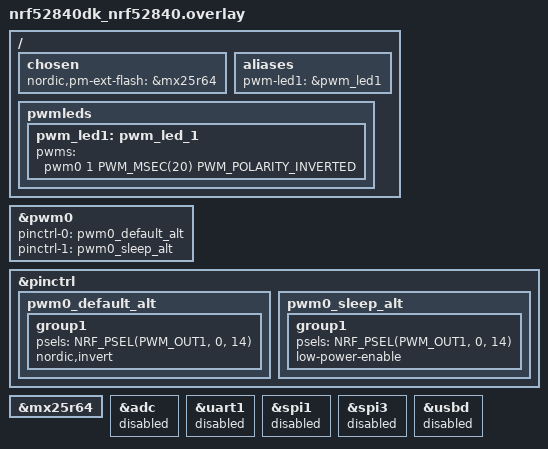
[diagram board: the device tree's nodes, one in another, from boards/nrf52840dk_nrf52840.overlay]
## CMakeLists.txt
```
#
# Copyright (c) 2021 Nordic Semiconductor ASA
#
# SPDX-License-Identifier: LicenseRef-Nordic-5-Clause
#

cmake_minimum_required(VERSION 3.20.0)

include(${CMAKE_CURRENT_LIST_DIR}/../../cmake/find_zephyr.cmake)

project(matter-light-bulb)

# NORDIC SDK APP START

# Include all source files that are located in the Matter common directory.
include(${ZEPHYR_NCS_MATTER_MODULE_DIR}/cmake/sample.cmake)

ncs_get_zap_parent_dir(ZAP_PARENT_DIR)

target_include_directories(app PRIVATE
  src
  ${ZAP_PARENT_DIR}
)

target_sources(app PRIVATE
  src/app_task.cpp
  src/main.cpp
  src/zcl_callbacks.cpp
  ${CHIP_ROOT}/src/app/persistence/DeferredAttributePersistenceProvider.cpp
)

ncs_configure_data_model()
# NORDIC SDK APP END
```

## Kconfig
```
#
# Copyright (c) 2022 Nordic Semiconductor
#
# SPDX-License-Identifier: LicenseRef-Nordic-5-Clause
#
mainmenu "Matter nRF Connect Light Bulb Example Application"

# Sample configuration used for Thread networking
if OPENTHREAD

choice OPENTHREAD_NORDIC_LIBRARY_CONFIGURATION
	default OPENTHREAD_NORDIC_LIBRARY_FTD
endchoice

choice OPENTHREAD_DEVICE_TYPE
	default OPENTHREAD_FTD
endchoice

choice OPENTHREAD_IMPLEMENTATION
	default OPENTHREAD_SOURCES
endchoice

endif # OPENTHREAD

config CHIP_WIFI
	default y if SHIELD_NRF7002EB2

source "$(ZEPHYR_CONNECTEDHOMEIP_MODULE_DIR)/config/nrfconnect/chip-module/Kconfig.features"
source "$(ZEPHYR_CONNECTEDHOMEIP_MODULE_DIR)/config/nrfconnect/chip-module/Kconfig.defaults"
source "Kconfig.zephyr"
```

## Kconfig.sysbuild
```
#
# Copyright (c) 2023 Nordic Semiconductor ASA
#
# SPDX-License-Identifier: LicenseRef-Nordic-5-Clause
#

#### Radio core selection
config NRF_DEFAULT_IPC_RADIO
	default y

# Enable IEEE802.15.4 serialization to network core
# This config automatically pulls in the `overlay-802154.conf` in the ipc_radio image
config NETCORE_IPC_RADIO_IEEE802154
	default y if SOC_SERIES_NRF53 && !WIFI_NRF70

# Enable Bluetooth serialization to network core
# This config automatically pulls in the `overlay-bt_hci_ipc.conf` in the ipc_radio image
config NETCORE_IPC_RADIO_BT_HCI_IPC
	default y if SOC_SERIES_NRF53

#### Bootloader
choice BOOTLOADER
	default BOOTLOADER_MCUBOOT if !BOARD_NRF21540DK && !BOARD_NATIVE_SIM
endchoice

if BOOTLOADER_MCUBOOT

#### DFU multi-image support
config DFU_MULTI_IMAGE_PACKAGE_BUILD
	default y

config DFU_MULTI_IMAGE_PACKAGE_APP
	default y

#### DFU network core configuration
if SOC_SERIES_NRF53

choice MCUBOOT_MODE
	default MCUBOOT_MODE_OVERWRITE_ONLY
endchoice

choice BOOT_SIGNATURE_TYPE
	default BOOT_SIGNATURE_TYPE_RSA
endchoice

config SECURE_BOOT_NETCORE
	default y

config NETCORE_APP_UPDATE
	default y

config DFU_MULTI_IMAGE_PACKAGE_NET
	default y

endif # SOC_SERIES_NRF53
endif # BOOTLOADER_MCUBOOT

#### Enable generating factory data
config MATTER_ADD_ON_FACTORY_DATA_GENERATE
	default y if !BOARD_NRF21540DK && !BOARD_NATIVE_SIM

source "share/sysbuild/Kconfig"
```

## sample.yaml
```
sample:
  description: Matter Light Bulb example
  name: Matter Light Bulb
common:
  tags:
    - sysbuild
    - ci_samples_matter
tests:
  sample.matter.light_bulb.debug:
    sysbuild: true
    build_only: true
    integration_platforms:
      - nrf54lm20dk/nrf54lm20b/cpuapp
      - nrf54lm20dk/nrf54lm20a/cpuapp
    platform_allow:
      - nrf5340dk/nrf5340/cpuapp
      - nrf54l15dk/nrf54l15/cpuapp
      - nrf54lm20dk/nrf54lm20b/cpuapp
      - nrf54lm20dk/nrf54lm20a/cpuapp
  sample.matter.light_bulb.nrf7002eb2.debug:
    sysbuild: true
    build_only: true
    extra_args:
      - light_bulb_SHIELD=nrf7002eb2
      - SB_CONFIG_WIFI_NRF70=y
    integration_platforms:
      - nrf54lm20dk/nrf54lm20b/cpuapp
      - nrf54lm20dk/nrf54lm20a/cpuapp
    platform_allow:
      - nrf54lm20dk/nrf54lm20b/cpuapp
      - nrf54lm20dk/nrf54lm20a/cpuapp
  sample.matter.light_bulb.nrf7120.debug:
    sysbuild: true
    build_only: true
    extra_args:
      - CONFIG_CHIP_WIFI=y
      - CONFIG_WIFI_NRF71_PATCH=y
      - EXTRA_DTC_OVERLAY_FILE=${ZEPHYR_NRFXLIB_MODULE_DIR}/nrf71_wifi/bins/0.1.0/nrf7120_wifi_patch.dtsi
    integration_platforms:
      - nrf7120dk/nrf7120/cpuapp
    platform_allow:
      - nrf7120dk/nrf7120/cpuapp
  sample.matter.light_bulb.release:
    sysbuild: true
    build_only: true
    extra_args:
      - FILE_SUFFIX=release
    integration_platforms:
      - nrf54lm20dk/nrf54lm20b/cpuapp
      - nrf54lm20dk/nrf54lm20a/cpuapp
    platform_allow:
      - nrf5340dk/nrf5340/cpuapp
      - nrf54l15dk/nrf54l15/cpuapp
      - nrf54lm20dk/nrf54lm20b/cpuapp
      - nrf54lm20dk/nrf54lm20a/cpuapp
  sample.matter.light_bulb.nrf7002eb2.release:
    sysbuild: true
    build_only: true
    extra_args:
      - FILE_SUFFIX=release
      - light_bulb_SHIELD=nrf7002eb2
      - SB_CONFIG_WIFI_NRF70=y
    integration_platforms:
      - nrf54lm20dk/nrf54lm20b/cpuapp
      - nrf54lm20dk/nrf54lm20a/cpuapp
    platform_allow:
      - nrf54lm20dk/nrf54lm20b/cpuapp
      - nrf54lm20dk/nrf54lm20a/cpuapp
  sample.matter.light_bulb.nrf7120.release:
    sysbuild: true
    build_only: true
    extra_args:
      - FILE_SUFFIX=release
      - CONFIG_CHIP_WIFI=y
      - CONFIG_WIFI_NRF71_PATCH=y
      - EXTRA_DTC_OVERLAY_FILE=${ZEPHYR_NRFXLIB_MODULE_DIR}/nrf71_wifi/bins/0.1.0/nrf7120_wifi_patch.dtsi
    integration_platforms:
      - nrf7120dk/nrf7120/cpuapp
    platform_allow:
      - nrf7120dk/nrf7120/cpuapp
  sample.matter.light_bulb.ffs:
    sysbuild: true
    build_only: true
    extra_args:
      - CONFIG_CHIP_COMMISSIONABLE_DEVICE_TYPE=y
      - CONFIG_CHIP_ROTATING_DEVICE_ID=y
      - CONFIG_CHIP_DEVICE_TYPE=257
    integration_platforms:
      - nrf54l15dk/nrf54l15/cpuapp
      - nrf54lm20dk/nrf54lm20b/cpuapp
      - nrf54lm20dk/nrf54lm20a/cpuapp
    platform_allow:
      - nrf5340dk/nrf5340/cpuapp
      - nrf54l15dk/nrf54l15/cpuapp
      - nrf54lm20dk/nrf54lm20b/cpuapp
      - nrf54lm20dk/nrf54lm20a/cpuapp
  sample.matter.light_bulb.nrf7002eb2.ffs:
    sysbuild: true
    build_only: true
    extra_args:
      - CONFIG_CHIP_COMMISSIONABLE_DEVICE_TYPE=y
      - CONFIG_CHIP_ROTATING_DEVICE_ID=y
      - CONFIG_CHIP_DEVICE_TYPE=257
      - light_bulb_SHIELD=nrf7002eb2
      - SB_CONFIG_WIFI_NRF70=y
    integration_platforms:
      - nrf54lm20dk/nrf54lm20b/cpuapp
      - nrf54lm20dk/nrf54lm20a/cpuapp
    platform_allow:
      - nrf54lm20dk/nrf54lm20b/cpuapp
      - nrf54lm20dk/nrf54lm20a/cpuapp
  sample.matter.light_bulb.nrf7120.ffs:
    sysbuild: true
    build_only: true
    extra_args:
      - CONFIG_CHIP_COMMISSIONABLE_DEVICE_TYPE=y
      - CONFIG_CHIP_ROTATING_DEVICE_ID=y
      - CONFIG_CHIP_DEVICE_TYPE=257
      - CONFIG_CHIP_WIFI=y
      - CONFIG_WIFI_NRF71_PATCH=y
      - EXTRA_DTC_OVERLAY_FILE=${ZEPHYR_NRFXLIB_MODULE_DIR}/nrf71_wifi/bins/0.1.0/nrf7120_wifi_patch.dtsi
    integration_platforms:
      - nrf7120dk/nrf7120/cpuapp
    platform_allow:
      - nrf7120dk/nrf7120/cpuapp
  sample.matter.light_bulb.debug.nrf21540ek_fwd:
    sysbuild: true
    build_only: true
    extra_args:
      - light_bulb_SHIELD=nrf21540ek
      - ipc_radio_SHIELD=nrf21540ek
    integration_platforms:
      - nrf5340dk/nrf5340/cpuapp
    platform_allow: nrf5340dk/nrf5340/cpuapp
  # Sample to execute load tests
  sample.matter.light_bulb.memory_profiling:
    sysbuild: true
    build_only: true
    extra_args:
      - CONFIG_CHIP_MEMORY_PROFILING=y
      - CONFIG_SHELL_MINIMAL=y
      - CONFIG_CHIP_FACTORY_RESET_TIME_MEASUREMENT=y
    platform_allow:
      - nrf5340dk/nrf5340/cpuapp
      - nrf54l15dk/nrf54l15/cpuapp
      - nrf54lm20dk/nrf54lm20b/cpuapp
      - nrf54lm20dk/nrf54lm20a/cpuapp
    integration_platforms:
      - nrf54l15dk/nrf54l15/cpuapp
      - nrf54lm20dk/nrf54lm20b/cpuapp
      - nrf54lm20dk/nrf54lm20a/cpuapp
  sample.matter.light_bulb.nrf7002eb2.memory_profiling:
    sysbuild: true
    build_only: true
    extra_args:
      - CONFIG_CHIP_MEMORY_PROFILING=y
      - CONFIG_SHELL_MINIMAL=y
      - CONFIG_CHIP_FACTORY_RESET_TIME_MEASUREMENT=y
      - light_bulb_SHIELD=nrf7002eb2
      - SB_CONFIG_WIFI_NRF70=y
    platform_allow:
      - nrf54lm20dk/nrf54lm20b/cpuapp
      - nrf54lm20dk/nrf54lm20a/cpuapp
    integration_platforms:
      - nrf54lm20dk/nrf54lm20b/cpuapp
      - nrf54lm20dk/nrf54lm20a/cpuapp
  sample.matter.light_bulb.nrf7120.memory_profiling:
    sysbuild: true
    build_only: true
    extra_args:
      - CONFIG_CHIP_MEMORY_PROFILING=y
      - CONFIG_SHELL_MINIMAL=y
      - CONFIG_CHIP_FACTORY_RESET_TIME_MEASUREMENT=y
      - CONFIG_CHIP_WIFI=y
      - CONFIG_WIFI_NRF71_PATCH=y
      - EXTRA_DTC_OVERLAY_FILE=${ZEPHYR_NRFXLIB_MODULE_DIR}/nrf71_wifi/bins/0.1.0/nrf7120_wifi_patch.dtsi
    integration_platforms:
      - nrf7120dk/nrf7120/cpuapp
    platform_allow:
      - nrf7120dk/nrf7120/cpuapp
  sample.matter.light_bulb.tfm:
    sysbuild: true
    build_only: true
    extra_args:
      - FILE_SUFFIX=tfm
    integration_platforms:
      - nrf54l15dk/nrf54l15/cpuapp/ns
    platform_allow:
      - nrf54l15dk/nrf54l15/cpuapp/ns
  sample.matter.light_bulb.nfc_commissioning:
    sysbuild: true
    build_only: true
    extra_args:
      - CONFIG_CHIP_NFC_BASED_COMMISSIONING=y
      - CONFIG_CHIP_NFC_ONBOARDING_PAYLOAD=n
    integration_platforms:
      - nrf54l15dk/nrf54l15/cpuapp
      - nrf54lm20dk/nrf54lm20b/cpuapp
    platform_allow:
      - nrf54l15dk/nrf54l15/cpuapp
      - nrf54lm20dk/nrf54lm20b/cpuapp
```

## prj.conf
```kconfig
#
# Copyright (c) 2022 Nordic Semiconductor ASA
#
# SPDX-License-Identifier: LicenseRef-Nordic-5-Clause
#

# Enable CHIP
CONFIG_CHIP=y
CONFIG_CHIP_PROJECT_CONFIG="src/chip_project_config.h"
CONFIG_CHIP_DEVICE_PRODUCT_NAME="Matter Light Bulb"

# Configure ZAP file name
CONFIG_MATTER_ZAP_FILE_PATH="${APPLICATION_CONFIG_DIR}/src/default_zap/light_bulb.zap"

# 32773 == 0x8005 (example lighting-app)
CONFIG_CHIP_DEVICE_PRODUCT_ID=32773
CONFIG_STD_CPP17=y

# Enable Matter pairing automatically on application start.
CONFIG_CHIP_ENABLE_PAIRING_AUTOSTART=y

# Enable Matter extended announcement and increase duration to 1 hour.
CONFIG_CHIP_BLE_EXT_ADVERTISING=y
CONFIG_CHIP_BLE_ADVERTISING_DURATION=60

# Add support for LEDs and buttons on Nordic development kits
CONFIG_DK_LIBRARY=y
CONFIG_PWM=y

# Bluetooth Low Energy configuration
CONFIG_BT_DEVICE_NAME="MatterLight"

# Other settings
CONFIG_THREAD_NAME=y
CONFIG_MPU_STACK_GUARD=y
CONFIG_RESET_ON_FATAL_ERROR=n
CONFIG_CHIP_LIB_SHELL=y
CONFIG_MATTER_TEST_SHELL=y

# Reduce application size
CONFIG_USE_SEGGER_RTT=n

# Enable Factory Data feature
CONFIG_CHIP_FACTORY_DATA=y
CONFIG_CHIP_FACTORY_DATA_BUILD=y
```

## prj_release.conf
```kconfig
#
# Copyright (c) 2022 Nordic Semiconductor ASA
#
# SPDX-License-Identifier: LicenseRef-Nordic-5-Clause
#

# Enable CHIP
CONFIG_CHIP=y
CONFIG_CHIP_PROJECT_CONFIG="src/chip_project_config.h"
CONFIG_CHIP_DEVICE_PRODUCT_NAME="Matter Light Bulb"

# Configure ZAP file name
CONFIG_MATTER_ZAP_FILE_PATH="${APPLICATION_CONFIG_DIR}/src/default_zap/light_bulb.zap"

# 32773 == 0x8005 (example lighting-app)
CONFIG_CHIP_DEVICE_PRODUCT_ID=32773
CONFIG_STD_CPP17=y

# Enable Matter pairing automatically on application start.
CONFIG_CHIP_ENABLE_PAIRING_AUTOSTART=y

# Enable Matter extended announcement and increase duration to 1 hour.
CONFIG_CHIP_BLE_EXT_ADVERTISING=y
CONFIG_CHIP_BLE_ADVERTISING_DURATION=60

# Add support for LEDs and buttons on Nordic development kits
CONFIG_DK_LIBRARY=y
CONFIG_PWM=y

# Bluetooth Low Energy configuration
CONFIG_BT_DEVICE_NAME="MatterLight"

# Enable system reset on fatal error
CONFIG_RESET_ON_FATAL_ERROR=y

# Disable all debug features
CONFIG_USE_SEGGER_RTT=n
CONFIG_SHELL=n
CONFIG_OPENTHREAD_SHELL=n
CONFIG_CONSOLE=n
CONFIG_UART_CONSOLE=n
CONFIG_SERIAL=n
CONFIG_LOG=n
CONFIG_LOG_MODE_MINIMAL=n
CONFIG_ASSERT_VERBOSE=n
CONFIG_ASSERT_NO_FILE_INFO=y
CONFIG_PRINTK=n
CONFIG_PRINTK_SYNC=n
CONFIG_THREAD_NAME=n
CONFIG_BOOT_BANNER=n

# Enable Factory Data feature
CONFIG_CHIP_FACTORY_DATA=y
CONFIG_CHIP_FACTORY_DATA_BUILD=y

# Enable Watchdog
CONFIG_MATTER_WATCHDOG=y

# Enable LTO to decrease the flash usage.
CONFIG_LTO=y
CONFIG_ISR_TABLES_LOCAL_DECLARATION=y
```

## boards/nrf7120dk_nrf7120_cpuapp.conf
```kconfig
#
# Copyright (c) 2026 Nordic Semiconductor
#
# SPDX-License-Identifier: LicenseRef-Nordic-5-Clause
#

# Lower System ON idle current: see lib_nrf71_idle_power. Keep the
# default RAM_RETAIN_FULL tier; RAM_RETAIN_UNUSED_ONLY has been observed
# to cause issues on Wi-Fi builds.
CONFIG_NRF71_IDLE_POWER=y

# TODO: MCUboot is currently not supported on the nRF7120 DK.
CONFIG_CHIP_BOOTLOADER_NONE=y

# TODO: Currently MRAM does not support clearing factory data, so we can not
# migrate the DAC private key
CONFIG_CHIP_CRYPTO_PSA_MIGRATE_DAC_PRIV_KEY=n

# TODO: Enabling low-power mode unconditionally gives BLE more radio time,
# allowing the device to connect to Wi-Fi and send responses over BLE.
CONFIG_NRF_WIFI_LOW_POWER=y

# TODO: Enable experimental ANT-SW support for nRF7120 DK.
CONFIG_MPSL_DYNAMIC_INTERRUPTS=n
CONFIG_MPSL_NRF71_ANTSW=y
```

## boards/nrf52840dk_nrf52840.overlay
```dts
/*
 * Copyright (c) 2021-2022 Nordic Semiconductor ASA
 *
 * SPDX-License-Identifier: LicenseRef-Nordic-5-Clause
 */

#include <nrf52840_partitions.dtsi>

/ {
	chosen {
		nordic,pm-ext-flash = &mx25r64;
	};

	/*
	 * By default, PWM module is only configured for led0 (LED1 on the board).
	 * The light bulb app, however, uses LED2 to show the state of the lighting,
	 * including its brightness level.
	 */
	aliases {
		pwm-led1 = &pwm_led1;
	};

	pwmleds {
		pwm_led1: pwm_led_1 {
			pwms = <&pwm0 1 PWM_MSEC(20) PWM_POLARITY_INVERTED>;
		};
	};
};

&pwm0 {
	pinctrl-0 = <&pwm0_default_alt>;
	pinctrl-1 = <&pwm0_sleep_alt>;
	pinctrl-names = "default", "sleep";
};

&pinctrl {
	pwm0_default_alt: pwm0_default_alt {
		group1 {
			psels = <NRF_PSEL(PWM_OUT1, 0, 14)>;
			nordic,invert;
		};
	};

	pwm0_sleep_alt: pwm0_sleep_alt {
		group1 {
			psels = <NRF_PSEL(PWM_OUT1, 0, 14)>;
			low-power-enable;
		};
	};
};

&mx25r64 {
	status = "okay";
};

/* Disable unused peripherals to reduce power consumption */
&adc {
	status = "disabled";
};

&uart1 {
	status = "disabled";
};

&spi1 {
	status = "disabled";
};

&spi3 {
	status = "disabled";
};

&usbd {
	status = "disabled";
};
```

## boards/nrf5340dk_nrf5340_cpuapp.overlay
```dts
/*
 * Copyright (c) 2021-2022 Nordic Semiconductor ASA
 *
 * SPDX-License-Identifier: LicenseRef-Nordic-5-Clause
 */

#include <nrf5340_cpuapp_partitions.dtsi>
#include <zephyr/dt-bindings/ipc_service/static_vrings.h>

/ {
	chosen {
		nordic,pm-ext-flash = &mx25r64;
	};

	/*
	 * By default, PWM module is only configured for led0 (LED1 on the board).
	 * The light bulb app, however, uses LED2 to show the state of the lighting,
	 * including its brightness level.
	 */
	aliases {
		pwm-led1 = &pwm_led1;
	};

	pwmleds {
		compatible = "pwm-leds";

		pwm_led1: pwm_led_1 {
			pwms = <&pwm0 1 PWM_MSEC(20) PWM_POLARITY_INVERTED>;
		};
	};
};

/* Set IPC thread priority to the highest value to not collide with other threads. */
&ipc0 {
	zephyr,priority = <0 PRIO_COOP>;
};

&pwm0 {
	pinctrl-0 = <&pwm0_default_alt>;
	pinctrl-1 = <&pwm0_sleep_alt>;
	pinctrl-names = "default", "sleep";
};

&pinctrl {
	pwm0_default_alt: pwm0_default_alt {
		group1 {
			psels = <NRF_PSEL(PWM_OUT1, 0, 29)>;
			nordic,invert;
		};
	};

	pwm0_sleep_alt: pwm0_sleep_alt {
		group1 {
			psels = <NRF_PSEL(PWM_OUT1, 0, 29)>;
			low-power-enable;
		};
	};
};

&mx25r64 {
	status = "okay";
};

/* Disable unused peripherals to reduce power consumption */
&adc {
	status = "disabled";
};

&spi2 {
	status = "disabled";
};

&usbd {
	status = "disabled";
};
```

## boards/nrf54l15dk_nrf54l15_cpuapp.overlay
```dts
/*
 * Copyright (c) 2024 Nordic Semiconductor ASA
 *
 * SPDX-License-Identifier: LicenseRef-Nordic-5-Clause
 */

#include <nrf54l15_cpuapp_partitions.dtsi>

/ {
	chosen {
		nordic,pm-ext-flash = &mx25r64;
	};

	aliases {
		/* Configure PWM module for led1 (LED2 on the board) */
		pwm-led1 = &pwm_led1;

		/* Use watchdog wdt31 as the application watchdog */
		watchdog0 = &wdt31;
	};

	pwmleds {
		compatible = "pwm-leds";

		pwm_led1: pwm_led_1 {
			pwms = <&pwm20 1 PWM_MSEC(20) PWM_POLARITY_NORMAL>;
		};
	};
};

&mx25r64 {
	status = "okay";
};

&pwm20 {
	status = "okay";
	pinctrl-0 = <&pwm_default>;
	pinctrl-1 = <&pwm_sleep>;
	pinctrl-names = "default", "sleep";
};

&pinctrl {
	pwm_default: pwm_default {
		group1 {
			psels = <NRF_PSEL(PWM_OUT1, 1, 10)>;
		};
	};

	pwm_sleep: pwm_sleep {
		group1 {
			psels = <NRF_PSEL(PWM_OUT1, 1, 10)>;
			low-power-enable;
		};
	};
};

&wdt31 {
	status = "okay";
};
```

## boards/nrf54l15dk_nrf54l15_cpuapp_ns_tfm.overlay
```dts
/*
 * Copyright (c) 2026 Nordic Semiconductor ASA
 *
 * SPDX-License-Identifier: LicenseRef-Nordic-5-Clause
 */

#include <nrf54l15_cpuapp_tfm_application_partitions.dtsi>

/ {
	chosen {
		nordic,pm-ext-flash = &mx25r64;
	};

	aliases {
		/* Configure PWM module for led1 (LED2 on the board) */
		pwm-led1 = &pwm_led1;

		/* Use watchdog wdt31 as the application watchdog */
		watchdog0 = &wdt31;
	};

	pwmleds {
		compatible = "pwm-leds";

		pwm_led1: pwm_led_1 {
			pwms = <&pwm20 1 PWM_MSEC(20) PWM_POLARITY_NORMAL>;
		};
	};
};

&mx25r64 {
	status = "okay";
};

&pwm20 {
	status = "okay";
	pinctrl-0 = <&pwm_default>;
	pinctrl-1 = <&pwm_sleep>;
	pinctrl-names = "default", "sleep";
};

&pinctrl {
	pwm_default: pwm_default {
		group1 {
			psels = <NRF_PSEL(PWM_OUT1, 1, 10)>;
		};
	};

	pwm_sleep: pwm_sleep {
		group1 {
			psels = <NRF_PSEL(PWM_OUT1, 1, 10)>;
			low-power-enable;
		};
	};
};

&wdt31 {
	status = "okay";
};

/* Change IRQ ids to handle button interrupts.
 * The default values for nRF54L15 are 219 and 269,
 * but with TF-M they are reserved for the secure domain
 * (218 and 268 are reserved for the non-secure domain).
 */
&gpiote20 {
	interrupts = <218 NRF_DEFAULT_IRQ_PRIORITY>;
};

&gpiote30 {
	interrupts = <268 NRF_DEFAULT_IRQ_PRIORITY>;
};
```

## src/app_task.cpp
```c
/*
 * Copyright (c) 2021 Nordic Semiconductor ASA
 *
 * SPDX-License-Identifier: LicenseRef-Nordic-5-Clause
 */

#include "app_task.h"

#include "app/matter_init.h"
#include "app/task_executor.h"

#if defined(CONFIG_PWM)
#include "pwm/pwm_device.h"
#endif

#include "clusters/identify.h"

#include <app-common/zap-generated/attributes/Accessors.h>
#include <app/persistence/AttributePersistenceProviderInstance.h>
#include <app/persistence/DefaultAttributePersistenceProvider.h>
#include <app/persistence/DeferredAttributePersistenceProvider.h>
#include <app/server/Server.h>
#include <setup_payload/OnboardingCodesUtil.h>

#include <zephyr/logging/log.h>

LOG_MODULE_DECLARE(app, CONFIG_CHIP_APP_LOG_LEVEL);

using namespace ::chip;
using namespace ::chip::app;
using namespace ::chip::DeviceLayer;

namespace
{
constexpr EndpointId kLightEndpointId = 1;
constexpr uint8_t kDefaultMinLevel = 0;
constexpr uint8_t kDefaultMaxLevel = 254;

Nrf::Matter::IdentifyCluster sIdentifyCluster(kLightEndpointId, true, []() {
	Nrf::PostTask([] { Nrf::GetBoard().GetLED(Nrf::DeviceLeds::LED2).Set(false); });
#if defined(CONFIG_PWM)
	Nrf::PostTask([] { AppTask::Instance().GetPWMDevice().ApplyLevel(); });
#endif
});

#if defined(CONFIG_PWM)
const struct pwm_dt_spec sLightPwmDevice = PWM_DT_SPEC_GET(DT_ALIAS(pwm_led1));
#endif

/* Define a custom attribute persister which makes actual write of the CurrentLevel attribute value
 * to the non-volatile storage only when it has remained constant for 5 seconds. This is to reduce
 * the flash wearout when the attribute changes frequently as a result of MoveToLevel command.
 * DeferredAttribute object describes a deferred attribute, but also holds a buffer with a value to
 * be written, so it must live so long as the DeferredAttributePersistenceProvider object.
 */
DeferredAttribute gCurrentLevelPersister(ConcreteAttributePath(kLightEndpointId, Clusters::LevelControl::Id,
							       Clusters::LevelControl::Attributes::CurrentLevel::Id));

/* Deferred persistence will be auto-initialized as soon as the default persistence is initialized */
DefaultAttributePersistenceProvider gSimpleAttributePersistence;
DeferredAttributePersistenceProvider gDeferredAttributePersister(gSimpleAttributePersistence,
								 Span<DeferredAttribute>(&gCurrentLevelPersister, 1),
								 System::Clock::Milliseconds32(5000));

#ifdef CONFIG_DK_LIBRARY
#define APPLICATION_BUTTON_MASK DK_BTN2_MSK
#else
#define APPLICATION_BUTTON_MASK 0
#endif
} /* namespace */

void AppTask::LightingActionEventHandler(const LightingEvent &event)
{
#if defined(CONFIG_PWM)
	Nrf::PWMDevice::Action_t action = Nrf::PWMDevice::INVALID_ACTION;
	int32_t actor = 0;
	if (event.Actor == LightingActor::Button) {
		action = Instance().mPWMDevice.IsTurnedOn() ? Nrf::PWMDevice::OFF_ACTION : Nrf::PWMDevice::ON_ACTION;
		actor = static_cast<int32_t>(event.Actor);
	}

	if (action == Nrf::PWMDevice::INVALID_ACTION || !Instance().mPWMDevice.InitiateAction(action, actor, NULL)) {
		LOG_INF("An action could not be initiated.");
	}
#else
	Nrf::GetBoard().GetLED(Nrf::DeviceLeds::LED2).Set(!Nrf::GetBoard().GetLED(Nrf::DeviceLeds::LED2).GetState());
#endif
}

void AppTask::ButtonEventHandler(Nrf::ButtonState state, Nrf::ButtonMask hasChanged)
{
	if ((APPLICATION_BUTTON_MASK & hasChanged) & state) {
		Nrf::PostTask([] {
			LightingEvent event;
			event.Actor = LightingActor::Button;
			LightingActionEventHandler(event);
		});
	}
}

#if defined(CONFIG_PWM)
void AppTask::ActionInitiated(Nrf::PWMDevice::Action_t action, int32_t actor)
{
	if (action == Nrf::PWMDevice::ON_ACTION) {
		LOG_INF("Turn On Action has been initiated");
	} else if (action == Nrf::PWMDevice::OFF_ACTION) {
		LOG_INF("Turn Off Action has been initiated");
	} else if (action == Nrf::PWMDevice::LEVEL_ACTION) {
		LOG_INF("Level Action has been initiated");
	}
}

void AppTask::ActionCompleted(Nrf::PWMDevice::Action_t action, int32_t actor)
{
	if (action == Nrf::PWMDevice::ON_ACTION) {
		LOG_INF("Turn On Action has been completed");
	} else if (action == Nrf::PWMDevice::OFF_ACTION) {
		LOG_INF("Turn Off Action has been completed");
	} else if (action == Nrf::PWMDevice::LEVEL_ACTION) {
		LOG_INF("Level Action has been completed");
	}

	if (actor == static_cast<int32_t>(LightingActor::Button)) {
		Instance().UpdateClusterState();
	}
}
#endif /* CONFIG_PWM */

void AppTask::UpdateClusterState()
{
	SystemLayer().ScheduleLambda([this] {
#if defined(CONFIG_PWM)
		/* write the new on/off value */
		Protocols::InteractionModel::Status status =
			Clusters::OnOff::Attributes::OnOff::Set(kLightEndpointId, mPWMDevice.IsTurnedOn());
#else
		Protocols::InteractionModel::Status status = Clusters::OnOff::Attributes::OnOff::Set(
			kLightEndpointId, Nrf::GetBoard().GetLED(Nrf::DeviceLeds::LED2).GetState());
#endif
		if (status != Protocols::InteractionModel::Status::Success) {
			LOG_ERR("Updating on/off cluster failed: %x", to_underlying(status));
		}

#if defined(CONFIG_PWM)
		/* write the current level */
		status = Clusters::LevelControl::Attributes::CurrentLevel::Set(kLightEndpointId, mPWMDevice.GetLevel());
#else
		/* write the current level */
		if (Nrf::GetBoard().GetLED(Nrf::DeviceLeds::LED2).GetState()) {
			status = Clusters::LevelControl::Attributes::CurrentLevel::Set(kLightEndpointId, 100);
		} else {
			status = Clusters::LevelControl::Attributes::CurrentLevel::Set(kLightEndpointId, 0);
		}
#endif

		if (status != Protocols::InteractionModel::Status::Success) {
			LOG_ERR("Updating level cluster failed: %x", to_underlying(status));
		}
	});
}

void AppTask::InitPWMDDevice()
{
#if defined(CONFIG_PWM)
	/* Initialize lighting device (PWM) */
	uint8_t minLightLevel = kDefaultMinLevel;
	Clusters::LevelControl::Attributes::MinLevel::Get(kLightEndpointId, &minLightLevel);

	uint8_t maxLightLevel = kDefaultMaxLevel;
	Clusters::LevelControl::Attributes::MaxLevel::Get(kLightEndpointId, &maxLightLevel);

	Clusters::LevelControl::Attributes::CurrentLevel::TypeInfo::Type currentLevel;
	Clusters::LevelControl::Attributes::CurrentLevel::Get(kLightEndpointId, currentLevel);

	int ret =
		mPWMDevice.Init(&sLightPwmDevice, minLightLevel, maxLightLevel, currentLevel.ValueOr(kDefaultMaxLevel));
	if (ret != 0) {
		LOG_ERR("Failed to initialize PWD device.");
	}

	mPWMDevice.SetCallbacks(ActionInitiated, ActionCompleted);
#endif
}

CHIP_ERROR AppTask::Init()
{
	/* Initialize Matter stack */
	ReturnErrorOnFailure(Nrf::Matter::PrepareServer(Nrf::Matter::InitData{ .mPostServerInitClbk = []() {
		app::SetAttributePersistenceProvider(&gDeferredAttributePersister);
		return gSimpleAttributePersistence.Init(Nrf::Matter::GetPersistentStorageDelegate());
	} }));

	if (!Nrf::GetBoard().Init(ButtonEventHandler)) {
		LOG_ERR("User interface initialization failed.");
		return CHIP_ERROR_INCORRECT_STATE;
	}

	/* Register Matter event handler that controls the connectivity status LED based on the captured Matter network
	 * state. */
	ReturnErrorOnFailure(Nrf::Matter::RegisterEventHandler(Nrf::Board::DefaultMatterEventHandler, 0));

	return Nrf::Matter::StartServer();
}

CHIP_ERROR AppTask::StartApp()
{
	ReturnErrorOnFailure(Init());

	while (true) {
		Nrf::DispatchNextTask();
	}

	return CHIP_NO_ERROR;
}
```

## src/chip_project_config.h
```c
/*
 * Copyright (c) 2021 Nordic Semiconductor ASA
 *
 * SPDX-License-Identifier: LicenseRef-Nordic-5-Clause
 */

#pragma once

#ifdef CONFIG_CHIP_MEMORY_PROFILING
#define CHIP_CONFIG_LOG_MODULE_SecureChannel_PROGRESS 0
#define CHIP_CONFIG_LOG_MODULE_FabricProvisioning_PROGRESS 0
#define CHIP_CONFIG_LOG_MODULE_InteractionModel_PROGRESS 0
#define CHIP_CONFIG_LOG_MODULE_InteractionModel_DETAIL 0
#define CHIP_CONFIG_LOG_MODULE_DataManagement_PROGRESS 0
#endif
```
